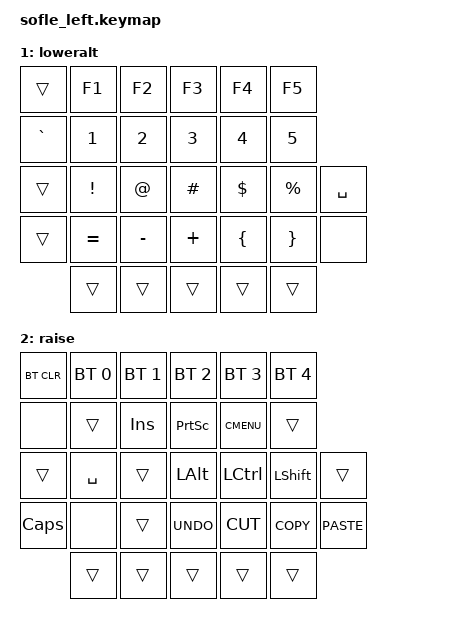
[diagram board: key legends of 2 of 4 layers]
/*
 * Copyright (c) 2020 The ZMK Contributors
 * SPDX-License-Identifier: MIT
 *
 * Sofle Left Half — ZMK v0.3
 * SuperMini NRF52840 (nice_nano_v2) + Sofle PCB
 * GitHub: https://github.com/neuromantech/zmk-config
 *
 * NOTE: RGB underglow NOT enabled — LEDs not soldered yet.
 *       OLED + encoders enabled.
 */

#include <behaviors.dtsi>
#include <dt-bindings/zmk/keys.h>
#include <dt-bindings/zmk/bt.h>
#include <dt-bindings/zmk/ext_power.h>

#define BASE    0
#define LOWERALT 1
#define RAISE   2
#define ADJUST  3

/ {

    conditional_layers {
        compatible = "zmk,conditional-layers";
        adjust_layer {
            if-layers = <LOWERALT RAISE>;
            then-layer = <ADJUST>;
        };
    };

    keymap {
        compatible = "zmk,keymap";

        default_layer {
            display-name = "default";
/*
 * Left half (columns 0-5 + left spacebar at col 4, row 3)
 * ,-----------------------------------------------------------.
 * |  `  |  1  |  2  |  3  |  4  |  5  |
 * | ESC  |  Q  |  W  |  E  |  R  |  T  |
 * | TAB  |  A  |  S  |  D  |  F  |  G  |
 * | LSFT |  Z  |  X  |  C  |  V  |  B  |  [LEFT SPACE HALF]
 * |      | LGUI | LALT| LCTL|LOWER| RET |
 */
            bindings = <
&kp GRAVE   &kp N1    &kp N2    &kp N3    &kp N4    &kp N5
&kp ESC     &kp Q     &kp W     &kp E     &kp R     &kp T
&kp TAB     &kp A     &kp S     &kp D     &kp F     &kp G
&kp LSHFT   &kp Z     &kp X     &kp C     &kp V     &kp B        &kp SPACE
               &kp LGUI  &kp LALT  &kp LCTRL &mo LOWERALT &kp RET
            >;
            sensor-bindings = <&inc_dec_kp PG_UP PG_DN>,
                               <&inc_dec_kp PG_UP PG_DN>;
        };

        loweralt_layer {
            display-name = "loweralt";
/*
 * |     | F1  | F2  | F3  | F4  | F5  |
 * |  `  |  1  |  2  |  3  |  4  |  5  |
 * |     |  !  |  @  |  #  |  $  |  %  |
 * |     |  =  |  -  |  +  |  {  |  }  |  [LEFT SPACE HALF]
 * |     |     |     |     |     |     |
 */
            bindings = <
&trans    &kp F1    &kp F2    &kp F3    &kp F4    &kp F5
&kp GRAVE &kp N1    &kp N2    &kp N3    &kp N4    &kp N5
&trans    &kp EXCL  &kp AT    &kp HASH  &kp DLLR  &kp PRCNT                  &kp SPACE
&trans    &kp EQUAL &kp MINUS &kp PLUS  &kp LBRC  &kp RBRC  &none
               &trans    &trans    &trans    &trans    &trans
            >;
            sensor-bindings = <&inc_dec_kp PG_UP PG_DN>,
                               <&inc_dec_kp PG_UP PG_DN>;
        };

        raise_layer {
            display-name = "raise";
/*
 * | BTCLR| BT1 | BT2 | BT3 | BT4 | BT5 |
 * |      | INS | PSCR| MENU|     |     |
 * |      | ALT | CTRL| SHFT|     | CAPS|
 * |      | UNDO| CUT | COPY| PASTE|     |  [LEFT SPACE HALF]
 * |      |     |     |     |     |     |
 */
            bindings = <
&bt BT_CLR   &bt BT_SEL 0 &bt BT_SEL 1 &bt BT_SEL 2 &bt BT_SEL 3 &bt BT_SEL 4                  &none
&trans      &kp INS      &kp PSCRN    &kp K_CMENU  &trans       &trans                            &kp SPACE
&trans      &kp LALT     &kp LCTRL    &kp LSHFT    &trans       &kp CLCK                           &none
&trans      &kp K_UNDO   &kp K_CUT    &kp K_COPY   &kp K_PASTE  &trans
                  &trans       &trans       &trans       &trans
            >;
            sensor-bindings = <&inc_dec_kp PG_UP PG_DN>,
                               <&inc_dec_kp PG_UP PG_DN>;
        };

        adjust_layer {
            display-name = "adjust";
/*
 * | BTCLR  | BT1   | BT2   | BT3   | BT4   | BT5   |
 * | EXTPWR | F1    | F2    | F3    | F4    | F5    |
 * |        | F6    | F7    |       |       |       |
 * |        |       |       |       |       |       |  [LEFT SPACE HALF]
 * |        |       |       |       |       |       |
 */
            bindings = <
&bt BT_CLR        &bt BT_SEL 0    &bt BT_SEL 1    &bt BT_SEL 2    &bt BT_SEL 3    &bt BT_SEL 4                          &none
&ext_power EP_TOG &kp F1          &kp F2          &kp F3          &kp F4          &kp F5                                &none
&none             &kp F6          &kp F7          &none           &none           &none                                 &none
&none             &none           &none           &none           &none           &none             &kp SPACE   &none &none &none
                                  &none           &none           &none           &none             &none
            >;
        };
    };
};
